VERSION "HIPBNYYYYYYYYYYYYYYYYYYYYYYYYYYYYYYYYYYYYY/4/%%%/4/'%**4YYY///"

NS_ :

BS_:

BU_: SBU RMC

BO_ 3221225472 VECTOR__INDEPENDENT_SIG_MSG: 0 Vector__XXX
 SG_ SBU_BrTqFR_Nm : 0|16@1+ (1,0) [0|65535] "Nm" Vector__XXX
 SG_ SBU_BrTqReqRL : 0|16@1+ (1,0) [0|65535] "Nm" Vector__XXX
 SG_ SBU_BrTqReqRR : 0|16@1+ (1,0) [0|65535] "Nm" Vector__XXX
 SG_ SBU_BrTqReqFL : 0|16@1+ (1,0) [0|65535] "Nm" Vector__XXX

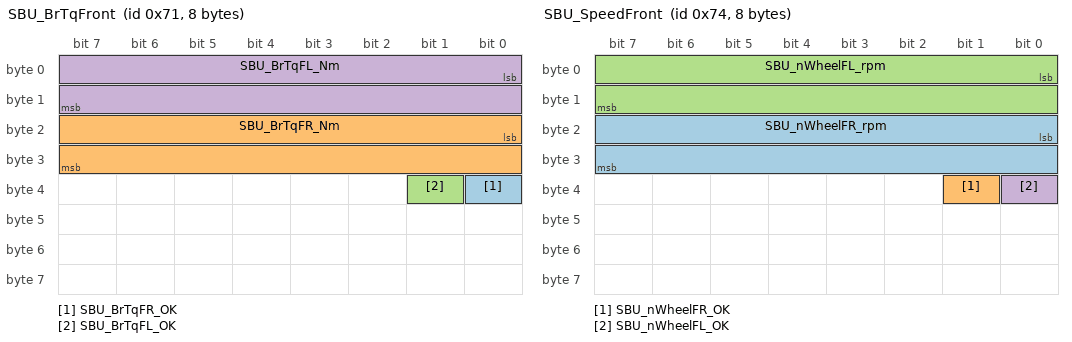
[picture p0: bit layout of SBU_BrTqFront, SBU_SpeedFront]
BO_ 113 SBU_BrTqFront: 8 SBU
 SG_ SBU_BrTqFR_OK : 32|1@1+ (1,0) [0|1] "" Vector__XXX
 SG_ SBU_BrTqFR_Nm : 16|16@1+ (1,0) [0|65535] "Nm" Vector__XXX
 SG_ SBU_BrTqFL_OK : 33|1@1+ (1,0) [0|1] "" Vector__XXX
 SG_ SBU_BrTqFL_Nm : 0|16@1+ (1,0) [0|65535] "Nm" Vector__XXX

BO_ 116 SBU_SpeedFront: 8 SBU
 SG_ SBU_nWheelFR_rpm : 16|16@1- (0.1,0) [-3276.8|3276.7] "rpm" Vector__XXX
 SG_ SBU_nWheelFR_OK : 33|1@1+ (1,0) [0|1] "" Vector__XXX
 SG_ SBU_nWheelFL_rpm : 0|16@1- (0.1,0) [-3276.8|3276.7] "rpm" Vector__XXX
 SG_ SBU_nWheelFL_OK : 32|1@1+ (1,0) [0|1] "" Vector__XXX

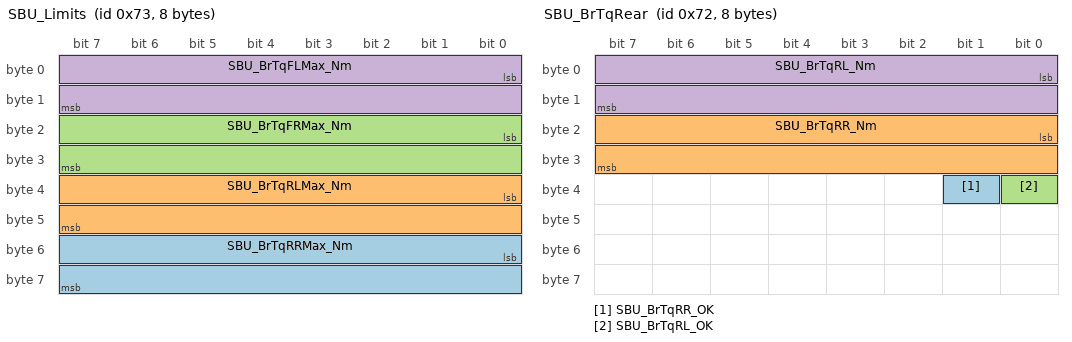
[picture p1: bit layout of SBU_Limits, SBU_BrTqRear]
BO_ 115 SBU_Limits: 8 SBU
 SG_ SBU_BrTqRRMax_Nm : 48|16@1+ (1,0) [0|65535] "Nm" Vector__XXX
 SG_ SBU_BrTqRLMax_Nm : 32|16@1+ (1,0) [0|65535] "Nm" Vector__XXX
 SG_ SBU_BrTqFRMax_Nm : 16|16@1+ (1,0) [0|65535] "Nm" Vector__XXX
 SG_ SBU_BrTqFLMax_Nm : 0|16@1+ (1,0) [0|65535] "Nm" Vector__XXX

BO_ 114 SBU_BrTqRear: 8 SBU
 SG_ SBU_BrTqRR_OK : 33|1@1+ (1,0) [0|1] "" Vector__XXX
 SG_ SBU_BrTqRR_Nm : 16|16@1+ (1,0) [0|65535] "Nm" Vector__XXX
 SG_ SBU_BrTqRL_OK : 32|1@1+ (1,0) [0|1] "" Vector__XXX
 SG_ SBU_BrTqRL_Nm : 0|16@1+ (1,0) [0|65535] "Nm" Vector__XXX

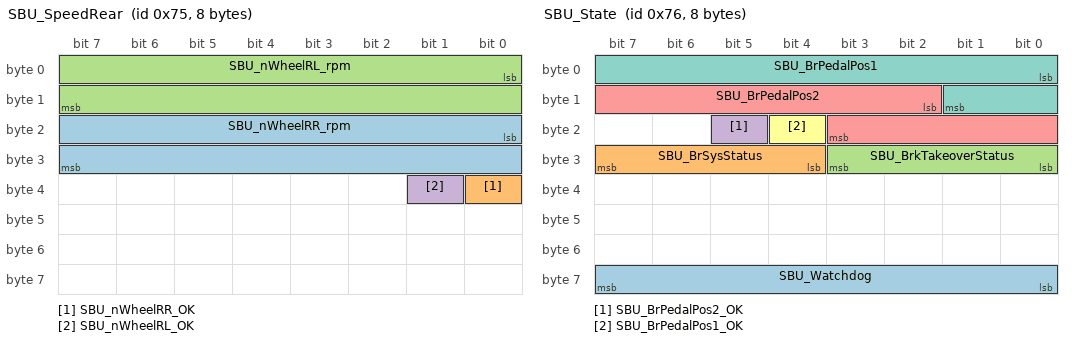
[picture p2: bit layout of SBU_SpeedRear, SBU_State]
BO_ 117 SBU_SpeedRear: 8 SBU
 SG_ SBU_nWheelRR_rpm : 16|16@1- (0.1,0) [-3276.8|3276.7] "rpm" Vector__XXX
 SG_ SBU_nWheelRR_OK : 32|1@1+ (1,0) [0|1] "" Vector__XXX
 SG_ SBU_nWheelRL_rpm : 0|16@1- (0.1,0) [-3276.8|3276.7] "rpm" Vector__XXX
 SG_ SBU_nWheelRL_OK : 33|1@1+ (1,0) [0|1] "" Vector__XXX

BO_ 118 SBU_State: 8 SBU
 SG_ SBU_Watchdog : 56|8@1+ (1,0) [0|255] "" Vector__XXX
 SG_ SBU_BrSysStatus : 28|4@1+ (1,0) [0|15] "" Vector__XXX
 SG_ SBU_BrkTakeoverStatus : 24|4@1+ (1,0) [0|15] "" Vector__XXX
 SG_ SBU_BrPedalPos2_OK : 21|1@1+ (1,0) [0|1] "" Vector__XXX
 SG_ SBU_BrPedalPos2 : 10|10@1+ (0.1,0) [0|102.3] "%" Vector__XXX
 SG_ SBU_BrPedalPos1_OK : 20|1@1+ (1,0) [0|1] "" Vector__XXX
 SG_ SBU_BrPedalPos1 : 0|10@1+ (0.1,0) [0|102.3] "%" Vector__XXX

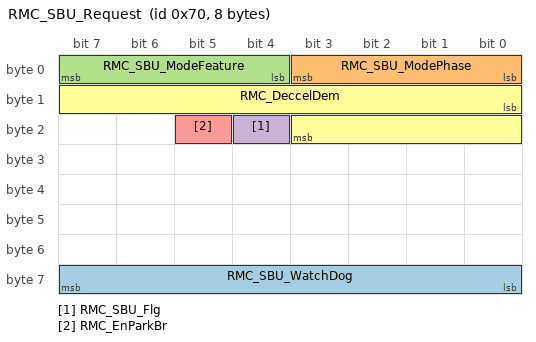
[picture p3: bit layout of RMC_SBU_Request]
BO_ 112 RMC_SBU_Request: 8 RMC
 SG_ RMC_SBU_WatchDog : 56|8@1+ (1,0) [0|255] "" Vector__XXX
 SG_ RMC_SBU_ModePhase : 0|4@1+ (1,0) [0|15] "" Vector__XXX
 SG_ RMC_SBU_ModeFeature : 4|4@1+ (1,0) [0|15] "" Vector__XXX
 SG_ RMC_SBU_Flg : 20|1@1+ (1,0) [0|1] "" Vector__XXX
 SG_ RMC_EnParkBr : 21|1@1+ (1,0) [0|1] "" Vector__XXX
 SG_ RMC_DeccelDem : 8|12@1+ (0.01,0) [0|40.95] "m/s^2" Vector__XXX

CM_ BO_ 3221225472 "This is a message for not used signals, created by Vector CANdb++ DBC OLE DB Provider.";
BA_DEF_ BO_  "GenMsgCycleTime" INT 0 1000;
BA_DEF_  "BusType" STRING ;
BA_DEF_DEF_  "GenMsgCycleTime" 0;
BA_DEF_DEF_  "BusType" "CAN";
BA_ "GenMsgCycleTime" BO_ 113 10;
BA_ "GenMsgCycleTime" BO_ 116 10;
BA_ "GenMsgCycleTime" BO_ 115 100;
BA_ "GenMsgCycleTime" BO_ 114 10;
BA_ "GenMsgCycleTime" BO_ 117 10;
BA_ "GenMsgCycleTime" BO_ 118 10;
BA_ "GenMsgCycleTime" BO_ 112 10;
VAL_ 112 RMC_SBU_ModePhase 4 "Phase 4" 3 "Phase 3" 2 "Phase 2" 1 "Phase 1" ;
VAL_ 112 RMC_SBU_ModeFeature 6 "AD" 5 "IPA" 4 "PCB" 3 "ISA" 2 "ACC" 1 "AEB" ;
